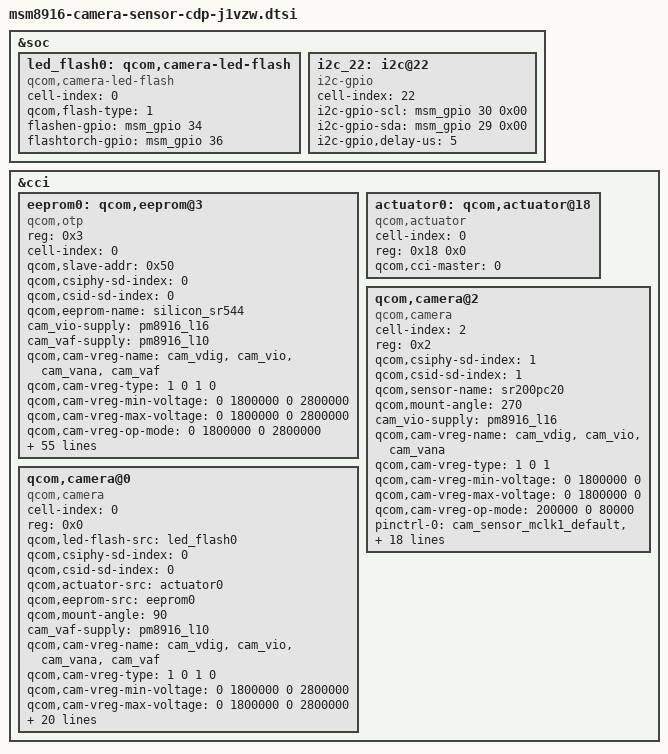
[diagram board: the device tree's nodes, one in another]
/*
 * Copyright (c) 2014, The Linux Foundation. All rights reserved.
 *
 * This program is free software; you can redistribute it and/or modify
 * it under the terms of the GNU General Public License version 2 and
 * only version 2 as published by the Free Software Foundation.
 *
 * This program is distributed in the hope that it will be useful,
 * but WITHOUT ANY WARRANTY; without even the implied warranty of
 * MERCHANTABILITY or FITNESS FOR A PARTICULAR PURPOSE.  See the
 * GNU General Public License for more details.
 */


&soc {
   led_flash0: qcom,camera-led-flash {
        cell-index = <0>;
		compatible = "qcom,camera-led-flash";
		qcom,flash-type = <1>;
		flashen-gpio= <&msm_gpio 34 0x00>;
		flashtorch-gpio = <&msm_gpio 36 0x00>;
   };

	i2c_22: i2c@22 {
		cell-index = <22>;
		compatible = "i2c-gpio";
		i2c-gpio-scl = <&msm_gpio 30 0x00>;
		i2c-gpio-sda = <&msm_gpio 29 0x00>;
		i2c-gpio,delay-us = <5>;
/*
		eeprom0: qcom,eeprom@50 {
			compatible = "qcom,eeprom";
			reg = <0x50 0x0>;
			cell-index = <0>;
			qcom,slave-addr = <0x40>;
			qcom,eeprom-name = "silicon_sr544";
			cam_vio-supply = <&pm8916_l16>;
			cam_vaf-supply = <&pm8916_l10>;
			qcom,cam-vreg-name = "cam_vdig", "cam_vio", "cam_vana",
				"cam_vaf";
			qcom,cam-vreg-type = <1 0 1 0>;
			qcom,cam-vreg-min-voltage = <0 1800000 0 2800000>;
			qcom,cam-vreg-max-voltage = <0 1800000 0 2800000>;
			qcom,cam-vreg-op-mode = <0 1800000 0 2800000>;
			pinctrl-names = "eeprom_default", "eeprom_suspend";
			pinctrl-0 = <&cam_sensor_eeprom_default>;
			pinctrl-1 = <&cam_sensor_eeprom_sleep>;
			qcom,gpio-no-mux = <0>;
			gpios = <&msm_gpio 26 0>,
			        <&msm_gpio 33 0>,
			        <&msm_gpio 35 0>;
			qcom,gpio-vdig = <1>;
			qcom,gpio-reset = <2>;
			qcom,gpio-req-tbl-num = <0 1 2>;
			qcom,gpio-req-tbl-flags = <1 0 0>;
			qcom,gpio-req-tbl-label = "CAMIF_MCLK",
			       "CAM_VDIG",
			       "CAM_RESET1";
			qcom,cci-master = <0>;
			qcom,cam-power-seq-type = "sensor_gpio",  "sensor_vreg","sensor_vreg", "sensor_vreg", "sensor_vreg", "sensor_gpio", "sensor_gpio", "sensor_i2c_mux";
			qcom,cam-power-seq-val = "sensor_gpio_vdig","cam_vdig", "cam_vana","cam_vio","cam_vaf","sensor_gpio_reset","sensor_gpio_reset","none";
			qcom,cam-power-seq-cfg-val = <1 1 1 1 1 0 1 0>;
			qcom,cam-power-seq-delay =   <1 1 1 1 2 2 1 5>;
			qcom,num-blocks = <1>;
			qcom,page0 = <0 0 0 0 0 0>;
			qcom,poll0 = <0 0 0 0 0 0>;
			qcom,mem0 = <0x850 0x00 2 0 1 0>;
		};
*/
      };
};

&cci {
	eeprom0: qcom,eeprom@3 {
		compatible = "qcom,otp";
		reg = <0x3>;
		cell-index = <0>;
		qcom,slave-addr = <0x50>;
		qcom,csiphy-sd-index = <0>;
		qcom,csid-sd-index = <0>;
		qcom,eeprom-name = "silicon_sr544";
		cam_vio-supply = <&pm8916_l16>;
		cam_vaf-supply = <&pm8916_l10>;
		qcom,cam-vreg-name = "cam_vdig", "cam_vio", "cam_vana", "cam_vaf";
		qcom,cam-vreg-type = <1 0 1 0>;
		qcom,cam-vreg-min-voltage = <0 1800000 0 2800000>;
		qcom,cam-vreg-max-voltage = <0 1800000 0 2800000>;
		qcom,cam-vreg-op-mode = <0 1800000 0 2800000>;
		pinctrl-names = "cam_default", "cam_suspend";
		pinctrl-0 = <&cam_sensor_mclk0_default>;
		pinctrl-1 = <&cam_sensor_mclk0_sleep>;
		gpios = <&msm_gpio 26 0>,
			  <&msm_gpio 33 0>,
			  <&msm_gpio 35 0>,
			  <&msm_gpio 16 0>,
			  <&msm_gpio 100 0>;
		qcom,gpio-vdig = <1>;
		qcom,gpio-reset = <2>;
		qcom,gpio-standby = <3>;
		qcom,gpio-vana = <4>;
		qcom,gpio-req-tbl-num = <0 1 2 3 4>;
		qcom,gpio-req-tbl-flags = <1 0 0 0 0>;
		qcom,gpio-req-tbl-label = "CAMIF_MCLK",
			"CAM_VDIG",
			"CAM_RESET1",
			"CAM_STBY1",
			"CAM_VANA";
		qcom,sensor-position = <0>;
		qcom,sensor-mode = <0>;
		qcom,cci-master = <0>;
		qcom,cam-power-seq-type = "sensor_gpio", "sensor_vreg", "sensor_gpio", "sensor_gpio",    "sensor_vreg", "sensor_gpio", "sensor_clk", "sensor_gpio", "sensor_gpio", "sensor_i2c_mux";
		qcom,cam-power-seq-val = "sensor_gpio_standby", "cam_vaf", "sensor_gpio_vdig", "sensor_gpio_vana", "cam_vio", "sensor_gpio_standby", "sensor_cam_mclk", "sensor_gpio_reset","sensor_gpio_reset","none";
		qcom,cam-power-seq-cfg-val = <0 1 1 1  1 1 26022000 0 1 0>;
		qcom,cam-power-seq-delay =   <1 2 1 1  0 1 5 10 3 5>;
		status = "ok";
		clocks = <&clock_gcc clk_mclk0_clk_src>,
			   <&clock_gcc clk_gcc_camss_mclk0_clk>;
		clock-names = "cam_src_clk", "cam_clk";
		qcom,num-blocks = <8>;
		qcom,page0 = <0 0 0 0 0 0>;
		qcom,poll0 = <0 0 0 0 0 0>;
		qcom,mem0 = <0x50 0x00 2 0 1 0>;
		qcom,page1 = <0 0 0 0 0 0>;
		qcom,poll1 = <0 0 0 0 0 0>;
		qcom,mem1 = <0x4 0x5C 2 0 1 0>;
		qcom,page2 = <0 0 0 0 0 0>;
		qcom,poll2 = <0 0 0 0 0 0>;
		qcom,mem2 = <0x70 0x60 2 0 1 0>;
		qcom,page3 = <0 0 0 0 0 0>;
		qcom,poll3 = <0 0 0 0 0 0>;
		qcom,mem3 = <0x4 0xDC 2 0 1 0>;
		qcom,page4 = <0 0 0 0 0 0>;
		qcom,poll4 = <0 0 0 0 0 0>;
		qcom,mem4 = <0x30 0xE0 2 0 1 0>;
		qcom,page5 = <0 0 0 0 0 0>;
		qcom,poll5 = <0 0 0 0 0 0>;
		qcom,mem5 = <0x4 0x11C 2 0 1 0>;
		qcom,page6 = <0 0 0 0 0 0>;
		qcom,poll6 = <0 0 0 0 0 0>;
		qcom,mem6 = <0x710 0x120 2 0 1 0>;
		qcom,page7 = <0 0 0 0 0 0>;
		qcom,poll7 = <0 0 0 0 0 0>;
		qcom,mem7 = <0x4 0x83C 2 0 1 0>;
		qcom,total-size = <0x850>;
	};

	actuator0: qcom,actuator@18 {
		compatible = "qcom,actuator";
		cell-index = <0>;
		reg = <0x18 0x0>;
		qcom,cci-master = <0>;
		};

	qcom,camera@0 {
		cell-index = <0>;
		compatible = "qcom,camera";
		reg = <0x0>;
		qcom,led-flash-src =<&led_flash0>;
		qcom,csiphy-sd-index = <0>;
		qcom,csid-sd-index = <0>;
		qcom,actuator-src = <&actuator0>;
		qcom,eeprom-src = <&eeprom0>;
		qcom,mount-angle = <90>;
		cam_vaf-supply = <&pm8916_l10>;
		qcom,cam-vreg-name = "cam_vdig", "cam_vio", "cam_vana", "cam_vaf";
		qcom,cam-vreg-type = <1 0 1 0>;
		qcom,cam-vreg-min-voltage = <0 1800000 0  2800000>;
		qcom,cam-vreg-max-voltage = <0 1800000 0  2800000>;
		qcom,cam-vreg-op-mode = <200000 0 80000 100000>;
		pinctrl-names = "cam_default", "cam_suspend";
		pinctrl-0 = <&cam_sensor_mclk0_default   &cam_sensor_rear_default>;
		pinctrl-1 = <&cam_sensor_mclk0_sleep  &cam_sensor_rear_sleep>;
		gpios = <&msm_gpio 26 0>,
			  <&msm_gpio 33 0>,
			  <&msm_gpio 35 0>,
			  <&msm_gpio 16 0>,
			  <&msm_gpio 100 0>;
		qcom,gpio-vdig = <1>;
		qcom,gpio-reset = <2>;
		qcom,gpio-standby = <3>;
		qcom,gpio-vana = <4>;
		qcom,gpio-req-tbl-num = <0 1 2 3 4>;
		qcom,gpio-req-tbl-flags = <1 0 0 0 0>;
		qcom,gpio-req-tbl-label = "CAMIF_MCLK",
			"CAM_VDIG",
			"CAM_RESET1",
			"CAM_STBY1",
			"CAM_VANA";
		qcom,sensor-position = <0>;
		qcom,sensor-mode = <0>;
		qcom,cci-master = <0>;
		status = "ok";
		clocks = <&clock_gcc clk_mclk0_clk_src>,
			   <&clock_gcc clk_gcc_camss_mclk0_clk>;
		clock-names = "cam_src_clk", "cam_clk";
	};



	qcom,camera@2 {
		cell-index = <2>;
		compatible = "qcom,camera";
		reg = <0x2>;
		qcom,csiphy-sd-index = <1>;
		qcom,csid-sd-index = <1>;
		qcom,sensor-name = "sr200pc20";
		qcom,mount-angle = <270>;
		cam_vio-supply = <&pm8916_l16>;
		qcom,cam-vreg-name = "cam_vdig", "cam_vio", "cam_vana";
		qcom,cam-vreg-type = <1 0 1>;
		qcom,cam-vreg-min-voltage = <0 1800000 0>;
		qcom,cam-vreg-max-voltage = <0 1800000 0>;
		qcom,cam-vreg-op-mode = <200000 0 80000>;
		pinctrl-names = "cam_default", "cam_suspend";
		pinctrl-0 = <&cam_sensor_mclk1_default  &cam_sensor_front_default>;
		pinctrl-1 = <&cam_sensor_mclk1_sleep  &cam_sensor_front_sleep>;
		gpios = <&msm_gpio 27 0>,
			  <&msm_gpio 33 0>,
			  <&msm_gpio 28 0>,
			  <&msm_gpio 17 0>,
			  <&msm_gpio 100 0>;
		qcom,gpio-vdig = <1>;
		qcom,gpio-reset = <2>;
		qcom,gpio-standby = <3>;
		qcom,gpio-vana = <4>;
		qcom,gpio-req-tbl-num = <0 1 2 3 4>;
		qcom,gpio-req-tbl-flags = <1 0 0 0 0>;
		qcom,gpio-req-tbl-label = "CAMIF_MCLK",
			"CAM_VDIG",
			"CAM_RESET",
			"CAM_STBY",
			"CAM_VANA";
		qcom,sensor-position = <1>;
		qcom,sensor-mode = <0>;
		qcom,cci-master = <0>;
		status = "ok";
		clocks = <&clock_gcc clk_mclk1_clk_src>,
			   <&clock_gcc clk_gcc_camss_mclk1_clk>;
		clock-names = "cam_src_clk", "cam_clk";
	};
/*
	qcom,camera@2 {
		cell-index = <2>;
		compatible = "qcom,camera";
		reg = <0x2>;
		qcom,csiphy-sd-index = <0>;
		qcom,csid-sd-index = <1>;
		qcom,sensor-name = "sr200pc20";
		qcom,mount-angle = <270>;
		cam_vio-supply = <&pm8916_l16>;
		qcom,cam-vreg-name = "cam_vdig", "cam_vio", "cam_vana";
		qcom,cam-vreg-type = <1 0 1>;
		qcom,cam-vreg-min-voltage = <0 1800000 0>;
		qcom,cam-vreg-max-voltage = <0 1800000 0>;
		qcom,cam-vreg-op-mode = <200000 0 80000>;
		pinctrl-names = "cam_default", "cam_suspend";
		pinctrl-0 = <&cam_sensor_mclk1_default &cam_sensor_front_default>;
		pinctrl-1 = <&cam_sensor_mclk1_sleep &cam_sensor_front_sleep>;
		gpios = <&msm_gpio 27 0>,
			  <&msm_gpio 28 0>,
			  <&msm_gpio 17 0>;
		qcom,gpio-reset = <1>;
		qcom,gpio-standby = <2>;
		qcom,gpio-req-tbl-num = <0 1 2>;
		qcom,gpio-req-tbl-flags = <1 0 0>;
		qcom,gpio-req-tbl-label = "CAMIF_MCLK",
			"CAM_RESET",
			"CAM_STBY";
		qcom,sensor-position = <1>;
		qcom,sensor-mode = <0>;
		qcom,cci-master = <0>;
		status = "ok";
		clocks = <&clock_gcc clk_mclk1_clk_src>,
			   <&clock_gcc clk_gcc_camss_mclk1_clk>;
		clock-names = "cam_src_clk", "cam_clk";
	};
*/
};
